# APM32F41x register map
File version: 1.0
CPU: CM4 r1p0, little endian, no MPU, no FPU, 3 interrupt priority bits
Registers are 32-bit, read-write, reset 0x0 unless marked. A register's access mark holds for its fields unless they carry their own. Offsets are from the block's base; [hi:lo] are bit positions; {n}, {i} and the like mark numbered series.

## DMC — Dynamic memory controler
Base 0xA0000000; alternate view of SMC
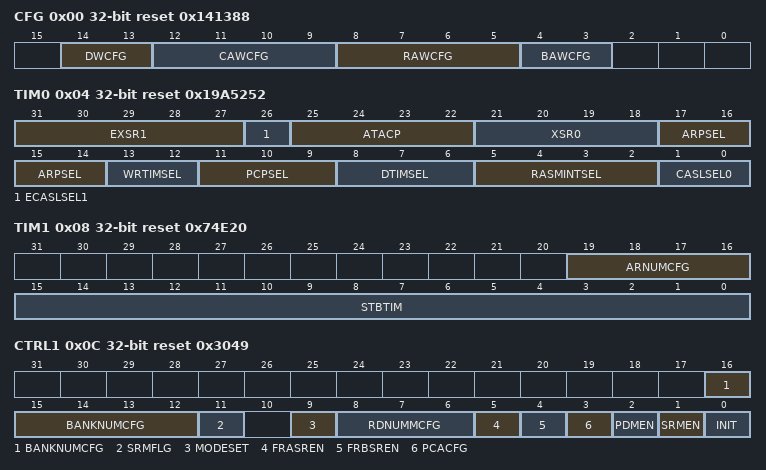
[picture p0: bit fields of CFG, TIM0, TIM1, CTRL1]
0x00 CFG reset 0x141388 — Configuraion register
  [14:13] DWCFG — Data Width Configure
  [12:9] CAWCFG — Column Address Width Configure
  [8:5] RAWCFG — Row Address Width Configure
  [4:3] BAWCFG — Bank Address Width Configure
0x04 TIM0 reset 0x19A5252 — Timing register 0
  [31:27] EXSR1
  [26] ECASLSEL1 — Extended CAS Latency
  [25:22] ATACP — Active to active
  [21:18] XSR0
  [17:14] ARPSEL — Auto-Refresh Period Select
  [13:12] WRTIMSEL
  [11:9] PCPSEL — Precharge Period Select
  [8:6] DTIMSEL — RAS To CAS Delay Time Select
  [5:2] RASMINTSEL — RAS Minimum Time Select
  [1:0] CASLSEL0 — CAS Latency Select
0x08 TIM1 reset 0x74E20 — Timing register 1
  [19:16] ARNUMCFG — Number Of Auto-Refresh During Initialization Configure
  [15:0] STBTIM — Stable Time
0x0C CTRL1 access per field reset 0x3049 — Control register 1
  [16:12] BANKNUMCFG rw — Number Of Open Banks Configure
  [11] SRMFLG ro — Self-refresh mode flag
  [9] MODESET rw — Mode Setup
  [8:6] RDNUMMCFG rw — Configure Number Of Registers Inserted In Read Data Path
  [5] FRASREN rw — Full Refresh After Exit Self-Refresh Mode
  [4] FRBSREN rw — Full Refresh Before Entering Self-Refresh Mode
  [3] PCACFG rw — Precharge Algorithm Configure
  [2] PDMEN rw — Put SDRM in Power-Down Mode Enable
  [1] SRMEN rw — Put SDRM in Self-Refresh Mode Enable
  [0] INIT rw — SDRAM Initialize
0x10 REF reset 0xC3 — refresh register
  [15:0] RCYCCFG
0x400 SW — switch register
  [0] MCSW — Memory Controller Function Switch
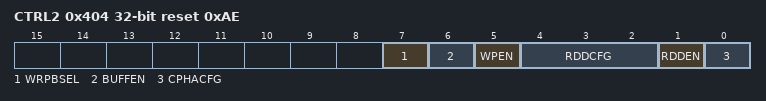
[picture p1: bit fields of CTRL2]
0x404 CTRL2 reset 0xAE — Control register 2
  [7] WRPBSEL, [6] BUFFEN, [5] WPEN, [4:2] RDDCFG, [1] RDDEN, [0] CPHACFG

## RNG — Random number generator
Base 0x50060800
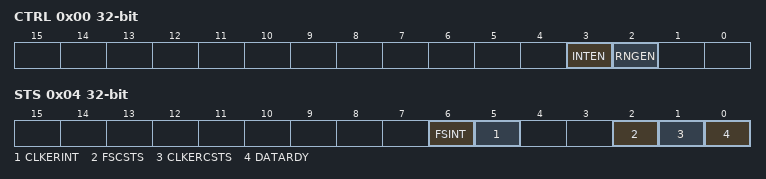
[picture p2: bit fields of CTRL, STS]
0x00 CTRL — control register
  [3] INTEN — Interrupt enable
  [2] RNGEN — Random number generator enable
0x04 STS access per field — status register
  [6] FSINT rw — Seed error interrupt status
  [5] CLKERINT rw — Clock error interrupt status
  [2] FSCSTS ro — Seed error current status
  [1] CLKERCSTS ro — Clock error current status
  [0] DATARDY ro — Data ready
0x08 DATA ro
  [31:0] DATA — Random data

## HASH — Hash processor
Base 0x50060400
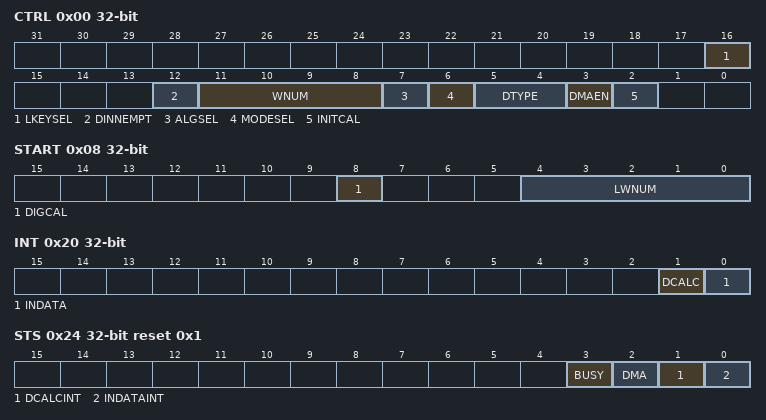
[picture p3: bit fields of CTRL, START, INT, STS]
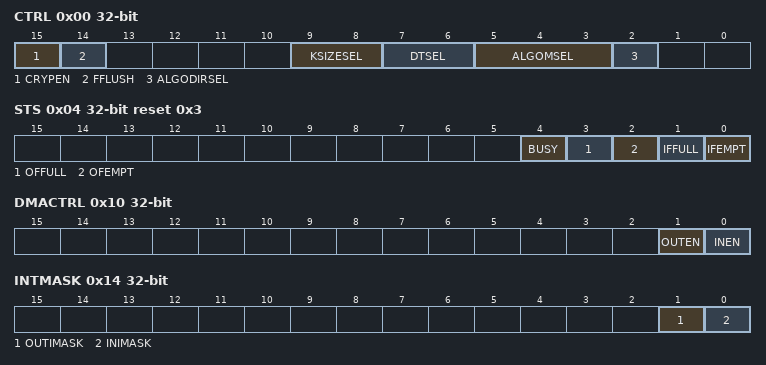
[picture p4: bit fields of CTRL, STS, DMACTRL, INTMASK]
0x00 CTRL access per field — control register
  [16] LKEYSEL rw — Long key selection
  [12] DINNEMPT ro — DIN not empty
  [11:8] WNUM ro — Number of words already pushed
  [7] ALGSEL rw — Algorithm selection
  [6] MODESEL rw — Mode selection
  [5:4] DTYPE rw — Data type selection
  [3] DMAEN rw — DMA enable
  [2] INITCAL wo — Initialize message digest calculation
0x04 INDATA — data input register
  [31:0] INDATA — Data input
0x08 START access per field
  [8] DIGCAL wo — Digest calculation
  [4:0] LWNUM rw — Number of valid bits in the last word of the message
{0xC+4i} DIG{i} ro (i=0..4) — digest registers
0x20 INT — interrupt enable register
  [1] DCALC — Digest calculation completion interrupt enable
  [0] INDATA — Data input interrupt enable
0x24 STS access per field reset 0x1 — status register
  [3] BUSY ro — Busy bit
  [2] DMA ro — DMA Status
  [1] DCALCINT rw — Digest calculation completion interrupt status
  [0] INDATAINT rw — Data input interrupt status
{0xF8+4i} CTSWAP{i} (i=0..50) — context swap registers

## CRYP — Cryptographic processor
Base 0x50060000
0x00 CTRL access per field — control register
  [15] CRYPEN rw — Cryptographic processor enable
  [14] FFLUSH wo — FIFO flush
  [9:8] KSIZESEL rw — Key size selection (AES mode only)
  [7:6] DTSEL rw — Data type selection
  [5:3] ALGOMSEL rw — Algorithm mode
  [2] ALGODIRSEL rw — Algorithm direction
0x04 STS ro reset 0x3 — status register
  [4] BUSY — Busy bit
  [3] OFFULL — Output FIFO full
  [2] OFEMPT — Output FIFO not empty
  [1] IFFULL — Input FIFO not full
  [0] IFEMPT — Input FIFO empty
0x08 DATAIN — data input register
  [31:0] DATAIN — Data input
0x0C DATAOUT ro — data output register
  [31:0] DATAOUT — Data output
0x10 DMACTRL — DMA control register
  [1] OUTEN — DMA output enable
  [0] INEN — DMA input enable
0x14 INTMASK — interrupt mask set/clear register
  [1] OUTIMASK — Output FIFO service interrupt mask
  [0] INIMASK — Input FIFO service interrupt mask
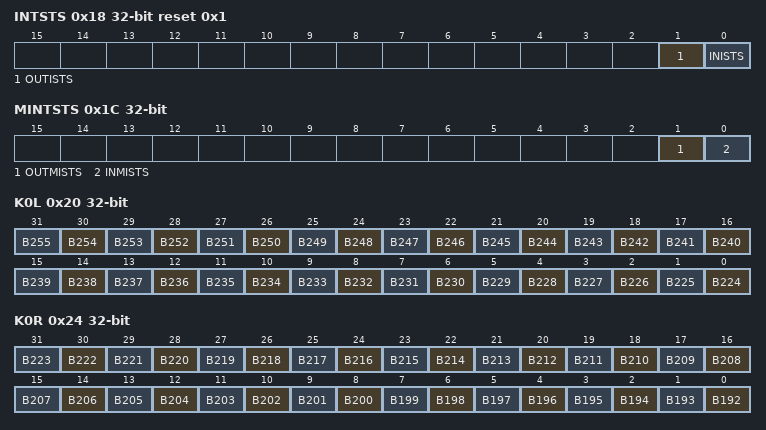
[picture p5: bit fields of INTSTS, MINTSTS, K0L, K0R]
0x18 INTSTS ro reset 0x1 — raw interrupt status register
  [1] OUTISTS — Output FIFO service raw interrupt status
  [0] INISTS — Input FIFO service raw interrupt status
0x1C MINTSTS ro — masked interrupt status register
  [1] OUTMISTS — Output FIFO service masked interrupt status
  [0] INMISTS — Input FIFO service masked interrupt status
0x20 K0L wo — key registers
  [n-224] B{n} (n=224..255)
0x24 K0R wo — key registers
  [n-192] B{n} (n=192..223)
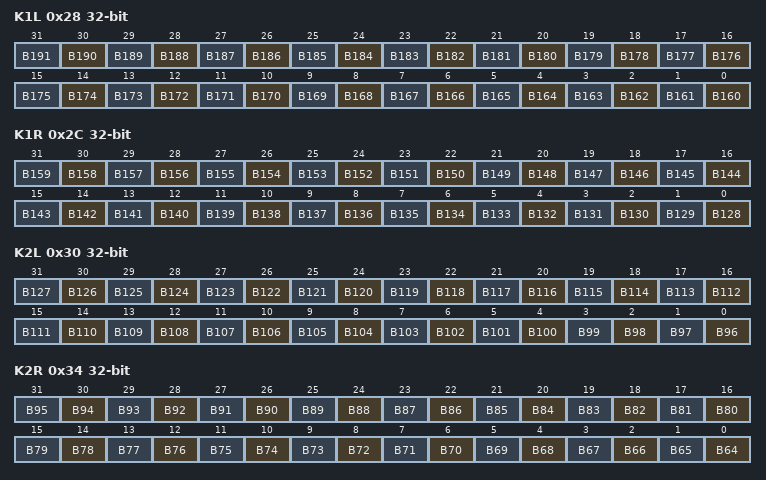
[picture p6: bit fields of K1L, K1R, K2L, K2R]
0x28 K1L wo — key registers
  [n-160] B{n} (n=160..191)
0x2C K1R wo — key registers
  [n-128] B{n} (n=128..159)
0x30 K2L wo — key registers
  [n-96] B{n} (n=96..127)
0x34 K2R wo — key registers
  [n-64] B{n} (n=64..95)
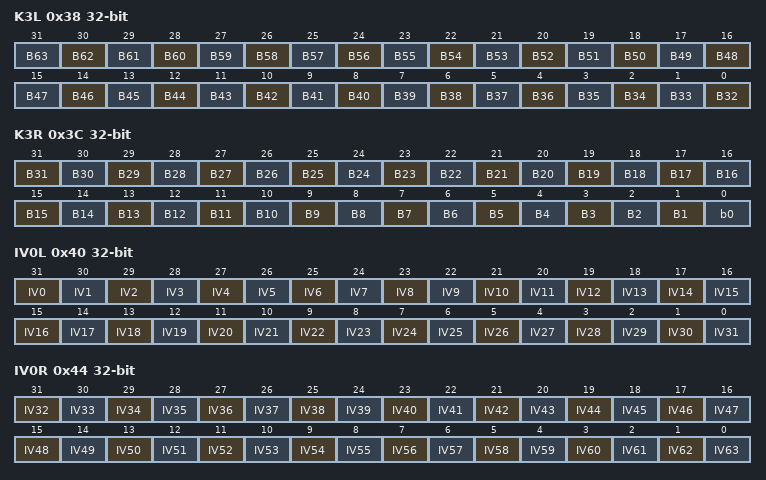
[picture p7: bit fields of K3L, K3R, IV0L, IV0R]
0x38 K3L wo — key registers
  [n-32] B{n} (n=32..63)
0x3C K3R wo — key registers
  [n] B{n} (n=1..31), [0] b0
0x40 IV0L — initialization vector registers
  [31-n] IV{n} (n=0..31)
0x44 IV0R — initialization vector registers
  [63-n] IV{n} (n=32..63)
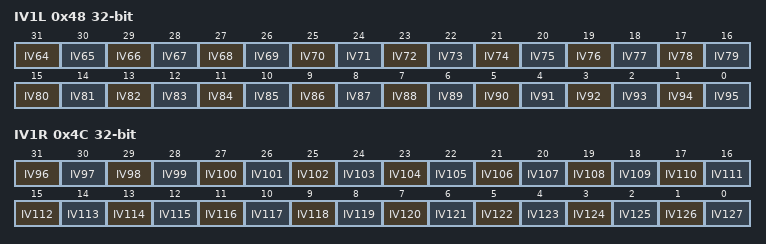
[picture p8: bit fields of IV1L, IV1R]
0x48 IV1L — initialization vector registers
  [95-n] IV{n} (n=64..95)
0x4C IV1R — initialization vector registers
  [127-n] IV{n} (n=96..127)
